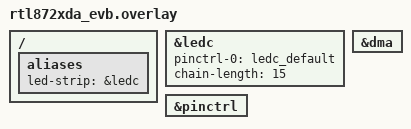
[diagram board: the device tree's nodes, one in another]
/ {
	aliases {
		led-strip = &ledc;
	};
};

&ledc {
	pinctrl-0 = <&ledc_default>;
	pinctrl-names = "default";
	chain-length = <15>;
	status = "okay";
};

&pinctrl {
	status = "okay";
};

/* Required only when built with CONFIG_LEDC_AMEBA_DMA=y; harmless otherwise. */
&dma {
	status = "okay";
};
